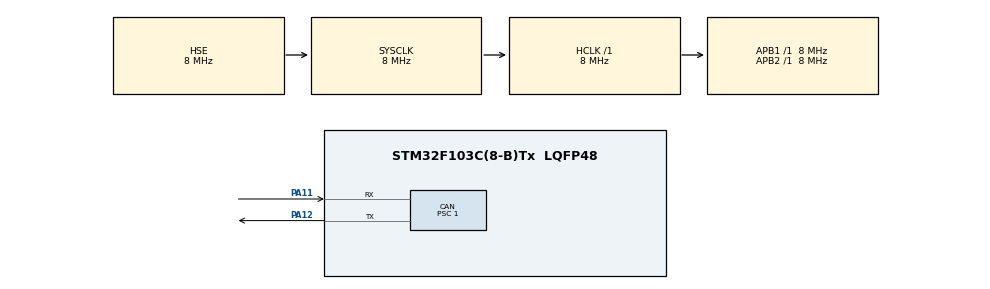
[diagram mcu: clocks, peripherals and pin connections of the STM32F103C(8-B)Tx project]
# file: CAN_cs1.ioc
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CAN.BS1=CAN_BS1_6TQ
CAN.CalculateBaudRate=1000000
CAN.CalculateTimeBit=1000
CAN.CalculateTimeQuantum=125.0
CAN.Mode=CAN_MODE_LOOPBACK
CAN.Prescaler=1
Mcu.Family=STM32F1
Mcu.Name=STM32F103C(8-B)Tx
Mcu.Package=LQFP48
NVIC.PriorityGroup=NVIC_PRIORITYGROUP_4
PA11.Mode=CAN_Activate
PA11.Signal=CAN_RX
PA12.Mode=CAN_Activate
PA12.Signal=CAN_TX
PA13.Mode=Serial_Wire
PA13.Signal=SYS_JTMS-SWDIO
PA14.Mode=Serial_Wire
PA14.Signal=SYS_JTCK-SWCLK
PD0-OSC_IN.Mode=HSE-External-Oscillator
PD0-OSC_IN.Signal=RCC_OSC_IN
PD1-OSC_OUT.Mode=HSE-External-Oscillator
PD1-OSC_OUT.Signal=RCC_OSC_OUT
ProjectManager.HeapSize=0x200
ProjectManager.StackSize=0x400
ProjectManager.TargetToolchain=STM32CubeIDE
RCC.AHBFreq_Value=8000000
RCC.APB1Freq_Value=8000000
RCC.APB1TimFreq_Value=8000000
RCC.APB2Freq_Value=8000000
RCC.APB2TimFreq_Value=8000000
RCC.HCLKFreq_Value=8000000
RCC.PLLSourceVirtual=RCC_PLLSOURCE_HSE
RCC.SYSCLKFreq_VALUE=8000000
RCC.SYSCLKSource=RCC_SYSCLKSOURCE_HSE
RCC.USBFreq_Value=16000000
board=custom

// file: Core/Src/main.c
/* USER CODE BEGIN Header */
/**
 ******************************************************************************
 * @file           : main.c
 * @brief          : Main program body
 ******************************************************************************
 * @attention
 *
 * Copyright (c) 2023 STMicroelectronics.
 * All rights reserved.
 *
 * This software is licensed under terms that can be found in the LICENSE file
 * in the root directory of this software component.
 * If no LICENSE file comes with this software, it is provided AS-IS.
 *
 ******************************************************************************
 */
/* USER CODE END Header */
#include "main.h"

CAN_HandleTypeDef hcan;

void SystemClock_Config(void);
static void MX_GPIO_Init(void);
static void MX_CAN_Init(void);

/* USER CODE BEGIN 0 */

void CAN_TX(uint32_t ID, uint8_t DLC, uint8_t* Payload){
	uint8_t no_free_txMailBox = 0;
	uint32_t pTxMailBox;
	CAN_TxHeaderTypeDef pHeader;

	pHeader.DLC = DLC;
	pHeader.IDE = CAN_ID_STD;
	pHeader.RTR = CAN_RTR_DATA;
	pHeader.StdId = ID;

	/* (++) HAL_CAN_GetTxMailboxesFreeLevel() to get the number of free Tx mailboxes. */
	no_free_txMailBox = HAL_CAN_GetTxMailboxesFreeLevel(&hcan);

	if(no_free_txMailBox != 0){
		//		(++) HAL_CAN_AddTxMessage() to request transmission of a new
		//		                 message.
		if(HAL_CAN_AddTxMessage(&hcan, &pHeader, Payload, &pTxMailBox) != HAL_OK){
			Error_Handler();
		}

		//		(++) HAL_CAN_IsTxMessagePending() to check if a message is pending
		//		                 in a Tx mailbox.
		/* Wait until TX Mailbox is transmitted (Polling Mechanism) */
		while(HAL_CAN_IsTxMessagePending(&hcan, pTxMailBox));
	}
}

void CAN_RX_Filter_Init(uint16_t STD_Filter_ID, uint16_t STD_Filter_MASK){
	//	(#) Configure the reception filters using the following configuration
	//		  functions:
	//		(++) HAL_CAN_ConfigFilter()
	CAN_FilterTypeDef sFilterConfig;
	sFilterConfig.FilterActivation = CAN_FILTER_ENABLE;
	sFilterConfig.FilterBank = 0;
	sFilterConfig.FilterFIFOAssignment = CAN_FILTER_FIFO0;
	sFilterConfig.FilterIdHigh = STD_Filter_ID << 5;
	sFilterConfig.FilterIdLow = 0;
	sFilterConfig.FilterMaskIdHigh = STD_Filter_MASK << 5;
	sFilterConfig.FilterMaskIdLow = 0;
	sFilterConfig.FilterMode = CAN_FILTERMODE_IDMASK;
	sFilterConfig.FilterScale = CAN_FILTERSCALE_32BIT;

	if(HAL_CAN_ConfigFilter(&hcan, &sFilterConfig) != HAL_OK){
		Error_Handler();
	}
}

void CAN_RX(uint32_t *ID, uint8_t *DLC, uint8_t* Payload){
	CAN_RxHeaderTypeDef pHeader;
	//	(#) Reception:
	//		(++) Monitor reception of message using HAL_CAN_GetRxFifoFillLevel()
	//			 until at least one message is received.
	//		(++) Then get the message using HAL_CAN_GetRxMessage().

	/* Wait until receive can message */
	while(!HAL_CAN_GetRxFifoFillLevel(&hcan, CAN_FILTER_FIFO0));
	if(HAL_CAN_GetRxMessage(&hcan, CAN_FILTER_FIFO0, &pHeader, Payload) != HAL_OK){
		Error_Handler();
	}
	*ID = pHeader.StdId;
	*DLC = pHeader.DLC;
}

/* USER CODE END 0 */

int main(void)
{

  /* MCU Configuration--------------------------------------------------------*/

  /* Reset of all peripherals, Initializes the Flash interface and the Systick. */
  HAL_Init();

  /* Configure the system clock */
  SystemClock_Config();

  /* Initialize all configured peripherals */
  MX_GPIO_Init();
  MX_CAN_Init();
  /* USER CODE BEGIN 2 */

	/* Filter IDs */
	CAN_RX_Filter_Init(0x3FF, 0x3FF);

	/* Start bxCAN (running state) */
	if(HAL_CAN_Start(&hcan) != HAL_OK){
		Error_Handler();
	}

	uint8_t TX_DATA[8] = {'C', 'A', 'N', ' ', 'N', 'O', ':', ' '};
	uint8_t RXDLC, FrameNo = 0;
	uint32_t RXID;
	uint8_t RX_DATA[8];

  /* USER CODE END 2 */

  /* Infinite loop */
	while (1)
	{

    /* USER CODE BEGIN 3 */
		TX_DATA[7] = FrameNo++;
		CAN_TX(0x3FF, 8, TX_DATA);
		CAN_RX(&RXID, &RXDLC, RX_DATA);
	}
  /* USER CODE END 3 */
}

void SystemClock_Config(void)
{
  RCC_OscInitTypeDef RCC_OscInitStruct = {0};
  RCC_ClkInitTypeDef RCC_ClkInitStruct = {0};

  /** Initializes the RCC Oscillators according to the specified parameters
  * in the RCC_OscInitTypeDef structure.
  */
  RCC_OscInitStruct.OscillatorType = RCC_OSCILLATORTYPE_HSE;
  RCC_OscInitStruct.HSEState = RCC_HSE_ON;
  RCC_OscInitStruct.PLL.PLLState = RCC_PLL_NONE;
  if (HAL_RCC_OscConfig(&RCC_OscInitStruct) != HAL_OK)
  {
    Error_Handler();
  }

  /** Initializes the CPU, AHB and APB buses clocks
  */
  RCC_ClkInitStruct.ClockType = RCC_CLOCKTYPE_HCLK|RCC_CLOCKTYPE_SYSCLK
                              |RCC_CLOCKTYPE_PCLK1|RCC_CLOCKTYPE_PCLK2;
  RCC_ClkInitStruct.SYSCLKSource = RCC_SYSCLKSOURCE_HSE;
  RCC_ClkInitStruct.AHBCLKDivider = RCC_SYSCLK_DIV1;
  RCC_ClkInitStruct.APB1CLKDivider = RCC_HCLK_DIV1;
  RCC_ClkInitStruct.APB2CLKDivider = RCC_HCLK_DIV1;

  if (HAL_RCC_ClockConfig(&RCC_ClkInitStruct, FLASH_LATENCY_0) != HAL_OK)
  {
    Error_Handler();
  }
}

static void MX_CAN_Init(void)
{

  hcan.Instance = CAN1;
  hcan.Init.Prescaler = 1;
  hcan.Init.Mode = CAN_MODE_LOOPBACK;
  hcan.Init.SyncJumpWidth = CAN_SJW_1TQ;
  hcan.Init.TimeSeg1 = CAN_BS1_6TQ;
  hcan.Init.TimeSeg2 = CAN_BS2_1TQ;
  hcan.Init.TimeTriggeredMode = DISABLE;
  hcan.Init.AutoBusOff = DISABLE;
  hcan.Init.AutoWakeUp = DISABLE;
  hcan.Init.AutoRetransmission = DISABLE;
  hcan.Init.ReceiveFifoLocked = DISABLE;
  hcan.Init.TransmitFifoPriority = DISABLE;
  if (HAL_CAN_Init(&hcan) != HAL_OK)
  {
    Error_Handler();
  }

}

static void MX_GPIO_Init(void)
{

  /* GPIO Ports Clock Enable */
  __HAL_RCC_GPIOD_CLK_ENABLE();
  __HAL_RCC_GPIOA_CLK_ENABLE();

}

void Error_Handler(void)
{
	__disable_irq();
	while (1)
	{
	}
}
